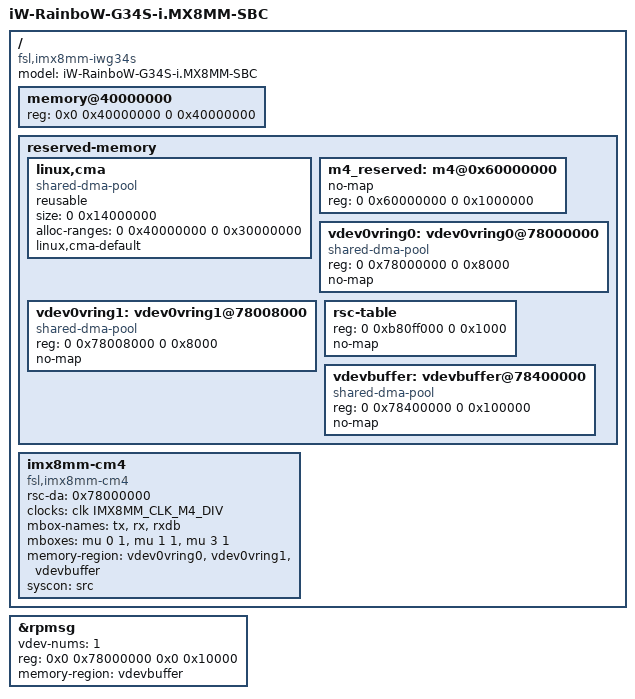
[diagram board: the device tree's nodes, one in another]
/*
 * Copyright (c) 2021 iWave Systems Technologies Pvt. Ltd.
 *
 * This program is free software; you can redistribute it and/or
 * modify it under the terms of the GNU General Public License
 * as published by the Free Software Foundation; either version 2
 * of the License, or (at your option) any later version.
 *
 * This program is distributed in the hope that it will be useful,
 * but WITHOUT ANY WARRANTY; without even the implied warranty of
 * MERCHANTABILITY or FITNESS FOR A PARTICULAR PURPOSE.  See the
 * GNU General Public License for more details.
 */

/dts-v1/;

#include "imx8mm-iwg34s.dtsi"

/ {
        model = "iW-RainboW-G34S-i.MX8MM-SBC";
        compatible = "fsl,imx8mm-iwg34s", "fsl,imx8mm";

        memory@40000000 {
                device_type = "memory";
                reg = <0x0 0x40000000 0 0x40000000>;
        };
	
	reserved-memory { /* RAM: 1GB Memory support */
		#address-cells = <2>;
		#size-cells = <2>;
		ranges;

		/* global autoconfigured region for contiguous allocations */
		linux,cma {
			compatible = "shared-dma-pool";
			reusable;
			size = <0 0x14000000>;
			alloc-ranges = <0 0x40000000 0 0x30000000>;
			linux,cma-default;
		};

		m4_reserved: m4@0x60000000 {
		     no-map;
		     reg = <0 0x60000000 0 0x1000000>;
	     	};

		vdev0vring0: vdev0vring0@78000000 {
		     compatible = "shared-dma-pool";
		     reg = <0 0x78000000 0 0x8000>;
		     no-map;
	     	};

		vdev0vring1: vdev0vring1@78008000 {
		     compatible = "shared-dma-pool";
		     reg = <0 0x78008000 0 0x8000>;
		     no-map;
	     	};

	     	rsc-table {
		     reg = <0 0xb80ff000 0 0x1000>;
		     no-map;
	     	};

		vdevbuffer: vdevbuffer@78400000 {
		    compatible = "shared-dma-pool";
		    reg = <0 0x78400000 0 0x100000>;
		    no-map;
	    	};
	};

	imx8mm-cm4 {
		compatible = "fsl,imx8mm-cm4";
		rsc-da = <0x78000000>;
		clocks = <&clk IMX8MM_CLK_M4_DIV>;
		mbox-names = "tx", "rx", "rxdb";
		mboxes = <&mu 0 1
			&mu 1 1
			&mu 3 1>;
		memory-region = <&vdev0vring0>, <&vdev0vring1>, <&vdevbuffer>;
		syscon = <&src>;
	};
};

&rpmsg{
		/*
		 * 64K for one rpmsg instance:
		 * --0x78000000~0x7800ffff: pingpong
		 */
		vdev-nums = <1>;
		reg = <0x0 0x78000000 0x0 0x10000>;
		memory-region = <&vdevbuffer>;
		status = "okay";
};
